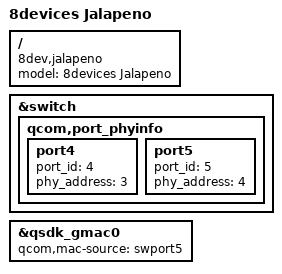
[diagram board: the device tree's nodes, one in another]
// SPDX-License-Identifier: GPL-2.0-or-later OR MIT
// Copyright (c) 2018, Robert Marko <robimarko@gmail.com>

#include "qcom-ipq4018-jalapeno.dtsi"

/ {
	model = "8devices Jalapeno";
	compatible = "8dev,jalapeno";
};

/* QSDK 10: retain this board's physical LAN/WAN port assignment. */
#define QSDK_LAN_BMP 0x10
#define QSDK_WAN_BMP 0x20
#define QSDK_WAN_PHY 4
#define QSDK_WAN_POLL 1
#include "qcom-ipq40xx-qsdk-10.dtsi"

&switch {
	qcom,port_phyinfo {
		port4 { port_id = <4>; phy_address = <3>; };
		port5 { port_id = <5>; phy_address = <4>; };
	};
};

&qsdk_gmac0 {
	qcom,mac-source = <&swport5>;
};
